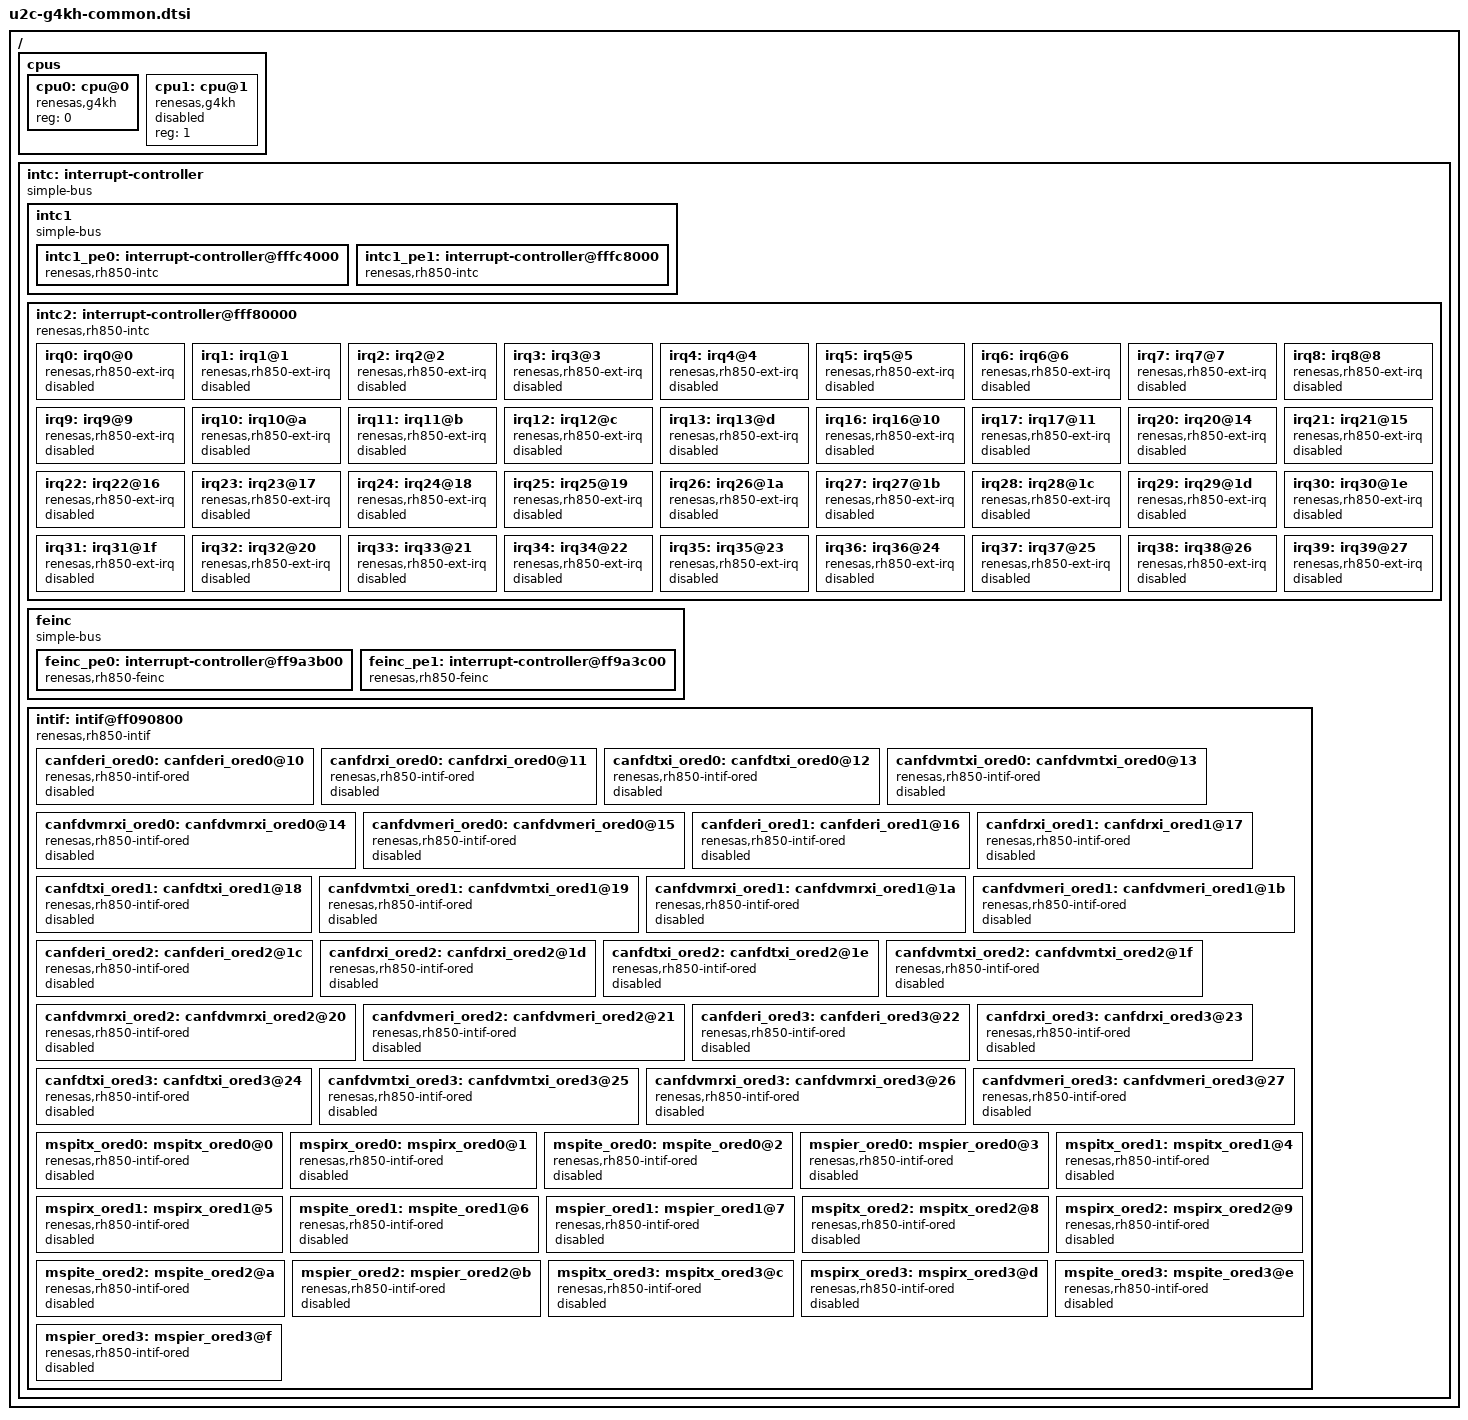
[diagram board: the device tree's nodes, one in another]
/*
 * Copyright (c) 2026 Renesas Electronics Corporation
 *
 * SPDX-License-Identifier: Apache-2.0
 */

#include <mem.h>
#include <freq.h>

/ {
	#address-cells = <1>;
	#size-cells = <1>;

	cpus {
		#address-cells = <1>;
		#size-cells = <0>;

		cpu0: cpu@0 {
			device_type = "cpu";
			compatible = "renesas,g4kh";
			reg = <0>;
			status = "okay";
		};

		cpu1: cpu@1 {
			device_type = "cpu";
			compatible = "renesas,g4kh";
			reg = <1>;
			status = "disabled";
		};
	};

	intc: interrupt-controller {
		#address-cells = <1>;
		#size-cells = <1>;
		compatible = "simple-bus";
		ranges;

		intc1: intc1 {
			#address-cells = <1>;
			#size-cells = <1>;
			compatible = "simple-bus";
			ranges;

			intc1_pe0: interrupt-controller@fffc4000 {
				#address-cells = <1>;
				#interrupt-cells = <2>;
				compatible = "renesas,rh850-intc";
				interrupt-controller;
				reg = <0xfffc4000 0x40>,
				      <0xfffc4100 0x80>;
				reg-names = "EIC", "EIBD";
				num-lines = <32>;
			};

			intc1_pe1: interrupt-controller@fffc8000 {
				#address-cells = <1>;
				#interrupt-cells = <2>;
				compatible = "renesas,rh850-intc";
				interrupt-controller;
				reg = <0xfffc8000 0x40>,
				      <0xfffc8100 0x80>;
				reg-names = "EIC", "EIBD";
				num-lines = <32>;
			};
		};

		intc2: interrupt-controller@fff80000 {
			#address-cells = <1>;
			#size-cells = <0>;
			#interrupt-cells = <2>;
			compatible = "renesas,rh850-intc";
			interrupt-controller;
			reg = <0xfff80000 0x4ac>,
			      <0xfff82000 0x958>;
			reg-names = "EIC", "EIBD";
			num-lines = <992>;

			irq0: irq0@0 {
				#address-cells = <1>;
				compatible = "renesas,rh850-ext-irq";
				reg = <0x00>;
				interrupt-controller;
				interrupts = <218 1>;
				#interrupt-cells = <2>;
				#irq-cells = <1>;
				status = "disabled";
			};

			irq1: irq1@1 {
				#address-cells = <1>;
				compatible = "renesas,rh850-ext-irq";
				reg = <0x01>;
				interrupt-controller;
				interrupts = <219 1>;
				#interrupt-cells = <2>;
				#irq-cells = <1>;
				status = "disabled";
			};

			irq2: irq2@2 {
				#address-cells = <1>;
				compatible = "renesas,rh850-ext-irq";
				reg = <0x02>;
				interrupt-controller;
				interrupts = <220 1>;
				#interrupt-cells = <2>;
				#irq-cells = <1>;
				status = "disabled";
			};

			irq3: irq3@3 {
				#address-cells = <1>;
				compatible = "renesas,rh850-ext-irq";
				reg = <0x03>;
				interrupt-controller;
				interrupts = <221 1>;
				#interrupt-cells = <2>;
				#irq-cells = <1>;
				status = "disabled";
			};

			irq4: irq4@4 {
				#address-cells = <1>;
				compatible = "renesas,rh850-ext-irq";
				reg = <0x04>;
				interrupt-controller;
				interrupts = <222 1>;
				#interrupt-cells = <2>;
				#irq-cells = <1>;
				status = "disabled";
			};

			irq5: irq5@5 {
				#address-cells = <1>;
				compatible = "renesas,rh850-ext-irq";
				reg = <0x05>;
				interrupt-controller;
				interrupts = <223 1>;
				#interrupt-cells = <2>;
				#irq-cells = <1>;
				status = "disabled";
			};

			irq6: irq6@6 {
				#address-cells = <1>;
				compatible = "renesas,rh850-ext-irq";
				reg = <0x06>;
				interrupt-controller;
				interrupts = <584 1>;
				#interrupt-cells = <2>;
				#irq-cells = <1>;
				status = "disabled";
			};

			irq7: irq7@7 {
				#address-cells = <1>;
				compatible = "renesas,rh850-ext-irq";
				reg = <0x07>;
				interrupt-controller;
				interrupts = <585 1>;
				#interrupt-cells = <2>;
				#irq-cells = <1>;
				status = "disabled";
			};

			irq8: irq8@8 {
				#address-cells = <1>;
				compatible = "renesas,rh850-ext-irq";
				reg = <0x08>;
				interrupt-controller;
				interrupts = <586 1>;
				#interrupt-cells = <2>;
				#irq-cells = <1>;
				status = "disabled";
			};

			irq9: irq9@9 {
				#address-cells = <1>;
				compatible = "renesas,rh850-ext-irq";
				reg = <0x09>;
				interrupt-controller;
				interrupts = <587 1>;
				#interrupt-cells = <2>;
				#irq-cells = <1>;
				status = "disabled";
			};

			irq10: irq10@a {
				#address-cells = <1>;
				compatible = "renesas,rh850-ext-irq";
				reg = <0x0a>;
				interrupt-controller;
				interrupts = <588 1>;
				#interrupt-cells = <2>;
				#irq-cells = <1>;
				status = "disabled";
			};

			irq11: irq11@b {
				#address-cells = <1>;
				compatible = "renesas,rh850-ext-irq";
				reg = <0x0b>;
				interrupt-controller;
				interrupts = <589 1>;
				#interrupt-cells = <2>;
				#irq-cells = <1>;
				status = "disabled";
			};

			irq12: irq12@c {
				#address-cells = <1>;
				compatible = "renesas,rh850-ext-irq";
				reg = <0x0c>;
				interrupt-controller;
				interrupts = <590 1>;
				#interrupt-cells = <2>;
				#irq-cells = <1>;
				status = "disabled";
			};

			irq13: irq13@d {
				#address-cells = <1>;
				compatible = "renesas,rh850-ext-irq";
				reg = <0x0d>;
				interrupt-controller;
				interrupts = <591 1>;
				#interrupt-cells = <2>;
				#irq-cells = <1>;
				status = "disabled";
			};

			irq16: irq16@10 {
				#address-cells = <1>;
				compatible = "renesas,rh850-ext-irq";
				reg = <0x10>;
				interrupt-controller;
				interrupts = <224 1>;
				#interrupt-cells = <2>;
				#irq-cells = <1>;
				status = "disabled";
			};

			irq17: irq17@11 {
				#address-cells = <1>;
				compatible = "renesas,rh850-ext-irq";
				reg = <0x11>;
				interrupt-controller;
				interrupts = <410 1>;
				#interrupt-cells = <2>;
				#irq-cells = <1>;
				status = "disabled";
			};

			irq20: irq20@14 {
				#address-cells = <1>;
				compatible = "renesas,rh850-ext-irq";
				reg = <0x14>;
				interrupt-controller;
				interrupts = <225 1>;
				#interrupt-cells = <2>;
				#irq-cells = <1>;
				status = "disabled";
			};

			irq21: irq21@15 {
				#address-cells = <1>;
				compatible = "renesas,rh850-ext-irq";
				reg = <0x15>;
				interrupt-controller;
				interrupts = <226 1>;
				#interrupt-cells = <2>;
				#irq-cells = <1>;
				status = "disabled";
			};

			irq22: irq22@16 {
				#address-cells = <1>;
				compatible = "renesas,rh850-ext-irq";
				reg = <0x16>;
				interrupt-controller;
				interrupts = <227 1>;
				#interrupt-cells = <2>;
				#irq-cells = <1>;
				status = "disabled";
			};

			irq23: irq23@17 {
				#address-cells = <1>;
				compatible = "renesas,rh850-ext-irq";
				reg = <0x17>;
				interrupt-controller;
				interrupts = <228 1>;
				#interrupt-cells = <2>;
				#irq-cells = <1>;
				status = "disabled";
			};

			irq24: irq24@18 {
				#address-cells = <1>;
				compatible = "renesas,rh850-ext-irq";
				reg = <0x18>;
				interrupt-controller;
				interrupts = <229 1>;
				#interrupt-cells = <2>;
				#irq-cells = <1>;
				status = "disabled";
			};

			irq25: irq25@19 {
				#address-cells = <1>;
				compatible = "renesas,rh850-ext-irq";
				reg = <0x19>;
				interrupt-controller;
				interrupts = <230 1>;
				#interrupt-cells = <2>;
				#irq-cells = <1>;
				status = "disabled";
			};

			irq26: irq26@1a {
				#address-cells = <1>;
				compatible = "renesas,rh850-ext-irq";
				reg = <0x1a>;
				interrupt-controller;
				interrupts = <231 1>;
				#interrupt-cells = <2>;
				#irq-cells = <1>;
				status = "disabled";
			};

			irq27: irq27@1b {
				#address-cells = <1>;
				compatible = "renesas,rh850-ext-irq";
				reg = <0x1b>;
				interrupt-controller;
				interrupts = <232 1>;
				#interrupt-cells = <2>;
				#irq-cells = <1>;
				status = "disabled";
			};

			irq28: irq28@1c {
				#address-cells = <1>;
				compatible = "renesas,rh850-ext-irq";
				reg = <0x1c>;
				interrupt-controller;
				interrupts = <411 1>;
				#interrupt-cells = <2>;
				#irq-cells = <1>;
				status = "disabled";
			};

			irq29: irq29@1d {
				#address-cells = <1>;
				compatible = "renesas,rh850-ext-irq";
				reg = <0x1d>;
				interrupt-controller;
				interrupts = <412 1>;
				#interrupt-cells = <2>;
				#irq-cells = <1>;
				status = "disabled";
			};

			irq30: irq30@1e {
				#address-cells = <1>;
				compatible = "renesas,rh850-ext-irq";
				reg = <0x1e>;
				interrupt-controller;
				interrupts = <413 1>;
				#interrupt-cells = <2>;
				#irq-cells = <1>;
				status = "disabled";
			};

			irq31: irq31@1f {
				#address-cells = <1>;
				compatible = "renesas,rh850-ext-irq";
				reg = <0x1f>;
				interrupt-controller;
				interrupts = <414 1>;
				#interrupt-cells = <2>;
				#irq-cells = <1>;
				status = "disabled";
			};

			irq32: irq32@20 {
				#address-cells = <1>;
				compatible = "renesas,rh850-ext-irq";
				reg = <0x20>;
				interrupt-controller;
				interrupts = <415 1>;
				#interrupt-cells = <2>;
				#irq-cells = <1>;
				status = "disabled";
			};

			irq33: irq33@21 {
				#address-cells = <1>;
				compatible = "renesas,rh850-ext-irq";
				reg = <0x21>;
				interrupt-controller;
				interrupts = <416 1>;
				#interrupt-cells = <2>;
				#irq-cells = <1>;
				status = "disabled";
			};

			irq34: irq34@22 {
				#address-cells = <1>;
				compatible = "renesas,rh850-ext-irq";
				reg = <0x22>;
				interrupt-controller;
				interrupts = <417 1>;
				#interrupt-cells = <2>;
				#irq-cells = <1>;
				status = "disabled";
			};

			irq35: irq35@23 {
				#address-cells = <1>;
				compatible = "renesas,rh850-ext-irq";
				reg = <0x23>;
				interrupt-controller;
				interrupts = <418 1>;
				#interrupt-cells = <2>;
				#irq-cells = <1>;
				status = "disabled";
			};

			irq36: irq36@24 {
				#address-cells = <1>;
				compatible = "renesas,rh850-ext-irq";
				reg = <0x24>;
				interrupt-controller;
				interrupts = <592 1>;
				#interrupt-cells = <2>;
				#irq-cells = <1>;
				status = "disabled";
			};

			irq37: irq37@25 {
				#address-cells = <1>;
				compatible = "renesas,rh850-ext-irq";
				reg = <0x25>;
				interrupt-controller;
				interrupts = <593 1>;
				#interrupt-cells = <2>;
				#irq-cells = <1>;
				status = "disabled";
			};

			irq38: irq38@26 {
				#address-cells = <1>;
				compatible = "renesas,rh850-ext-irq";
				reg = <0x26>;
				interrupt-controller;
				interrupts = <594 1>;
				#interrupt-cells = <2>;
				#irq-cells = <1>;
				status = "disabled";
			};

			irq39: irq39@27 {
				#address-cells = <1>;
				compatible = "renesas,rh850-ext-irq";
				reg = <0x27>;
				interrupt-controller;
				interrupts = <595 1>;
				#interrupt-cells = <2>;
				#irq-cells = <1>;
				status = "disabled";
			};
		};

		feinc: feinc {
			#address-cells = <1>;
			#size-cells = <1>;
			compatible = "simple-bus";
			ranges;

			feinc_pe0: interrupt-controller@ff9a3b00 {
				#address-cells = <1>;
				#interrupt-cells = <1>;
				compatible = "renesas,rh850-feinc";
				interrupt-controller;
				reg = <0xff9a3b00 0x4>,
				      <0xff9a3b04 0x4>,
				      <0xff9a3b08 0x4>;
				reg-names = "FEINTF", "FEINTMSK", "FEINTC";
				num-lines = <3>;
			};

			feinc_pe1: interrupt-controller@ff9a3c00 {
				#address-cells = <1>;
				#interrupt-cells = <1>;
				compatible = "renesas,rh850-feinc";
				interrupt-controller;
				reg = <0xff9a3c00 0x4>,
				      <0xff9a3c04 0x4>,
				      <0xff9a3c08 0x4>;
				reg-names = "FEINTF", "FEINTMSK", "FEINTC";
				num-lines = <3>;
			};
		};

		intif: intif@ff090800 {
			#address-cells = <1>;
			#size-cells = <0>;
			interrupt-parent = <&intc2>;
			compatible = "renesas,rh850-intif";
			reg = <0xff090800 0x13c>;

			canfderi_ored0: canfderi_ored0@10 {
				compatible = "renesas,rh850-intif-ored";
				#address-cells = <0>;
				reg = <0x10>;
				channel = <0>;
				interrupt-controller;
				interrupts = <106 1>;
				#interrupt-cells = <0>;
				status = "disabled";
			};

			canfdrxi_ored0: canfdrxi_ored0@11 {
				compatible = "renesas,rh850-intif-ored";
				#address-cells = <0>;
				reg = <0x11>;
				channel = <0>;
				interrupt-controller;
				interrupts = <107 1>;
				#interrupt-cells = <0>;
				status = "disabled";
			};

			canfdtxi_ored0: canfdtxi_ored0@12 {
				compatible = "renesas,rh850-intif-ored";
				#address-cells = <0>;
				reg = <0x12>;
				channel = <0>;
				interrupt-controller;
				interrupts = <108 1>;
				#interrupt-cells = <0>;
				status = "disabled";
			};

			canfdvmtxi_ored0: canfdvmtxi_ored0@13 {
				compatible = "renesas,rh850-intif-ored";
				#address-cells = <0>;
				reg = <0x13>;
				channel = <0>;
				interrupt-controller;
				interrupts = <109 1>;
				#interrupt-cells = <0>;
				status = "disabled";
			};

			canfdvmrxi_ored0: canfdvmrxi_ored0@14 {
				compatible = "renesas,rh850-intif-ored";
				#address-cells = <0>;
				reg = <0x14>;
				channel = <0>;
				interrupt-controller;
				interrupts = <110 1>;
				#interrupt-cells = <0>;
				status = "disabled";
			};

			canfdvmeri_ored0: canfdvmeri_ored0@15 {
				compatible = "renesas,rh850-intif-ored";
				#address-cells = <0>;
				reg = <0x15>;
				channel = <0>;
				interrupt-controller;
				interrupts = <111 1>;
				#interrupt-cells = <0>;
				status = "disabled";
			};

			canfderi_ored1: canfderi_ored1@16 {
				compatible = "renesas,rh850-intif-ored";
				#address-cells = <0>;
				reg = <0x16>;
				channel = <1>;
				interrupt-controller;
				interrupts = <112 1>;
				#interrupt-cells = <0>;
				status = "disabled";
			};

			canfdrxi_ored1: canfdrxi_ored1@17 {
				compatible = "renesas,rh850-intif-ored";
				#address-cells = <0>;
				reg = <0x17>;
				channel = <1>;
				interrupt-controller;
				interrupts = <113 1>;
				#interrupt-cells = <0>;
				status = "disabled";
			};

			canfdtxi_ored1: canfdtxi_ored1@18 {
				compatible = "renesas,rh850-intif-ored";
				#address-cells = <0>;
				reg = <0x18>;
				channel = <1>;
				interrupt-controller;
				interrupts = <114 1>;
				#interrupt-cells = <0>;
				status = "disabled";
			};

			canfdvmtxi_ored1: canfdvmtxi_ored1@19 {
				compatible = "renesas,rh850-intif-ored";
				#address-cells = <0>;
				reg = <0x19>;
				channel = <1>;
				interrupt-controller;
				interrupts = <115 1>;
				#interrupt-cells = <0>;
				status = "disabled";
			};

			canfdvmrxi_ored1: canfdvmrxi_ored1@1a {
				compatible = "renesas,rh850-intif-ored";
				#address-cells = <0>;
				reg = <0x1a>;
				channel = <1>;
				interrupt-controller;
				interrupts = <116 1>;
				#interrupt-cells = <0>;
				status = "disabled";
			};

			canfdvmeri_ored1: canfdvmeri_ored1@1b {
				compatible = "renesas,rh850-intif-ored";
				#address-cells = <0>;
				reg = <0x1b>;
				channel = <1>;
				interrupt-controller;
				interrupts = <117 1>;
				#interrupt-cells = <0>;
				status = "disabled";
			};

			canfderi_ored2: canfderi_ored2@1c {
				compatible = "renesas,rh850-intif-ored";
				#address-cells = <0>;
				reg = <0x1c>;
				channel = <2>;
				interrupt-controller;
				interrupts = <118 1>;
				#interrupt-cells = <0>;
				status = "disabled";
			};

			canfdrxi_ored2: canfdrxi_ored2@1d {
				compatible = "renesas,rh850-intif-ored";
				#address-cells = <0>;
				reg = <0x1d>;
				channel = <2>;
				interrupt-controller;
				interrupts = <119 1>;
				#interrupt-cells = <0>;
				status = "disabled";
			};

			canfdtxi_ored2: canfdtxi_ored2@1e {
				compatible = "renesas,rh850-intif-ored";
				#address-cells = <0>;
				reg = <0x1e>;
				channel = <2>;
				interrupt-controller;
				interrupts = <120 1>;
				#interrupt-cells = <0>;
				status = "disabled";
			};

			canfdvmtxi_ored2: canfdvmtxi_ored2@1f {
				compatible = "renesas,rh850-intif-ored";
				#address-cells = <0>;
				reg = <0x1f>;
				channel = <2>;
				interrupt-controller;
				interrupts = <121 1>;
				#interrupt-cells = <0>;
				status = "disabled";
			};

			canfdvmrxi_ored2: canfdvmrxi_ored2@20 {
				compatible = "renesas,rh850-intif-ored";
				#address-cells = <0>;
				reg = <0x20>;
				channel = <2>;
				interrupt-controller;
				interrupts = <122 1>;
				#interrupt-cells = <0>;
				status = "disabled";
			};

			canfdvmeri_ored2: canfdvmeri_ored2@21 {
				compatible = "renesas,rh850-intif-ored";
				#address-cells = <0>;
				reg = <0x21>;
				channel = <2>;
				interrupt-controller;
				interrupts = <123 1>;
				#interrupt-cells = <0>;
				status = "disabled";
			};

			canfderi_ored3: canfderi_ored3@22 {
				compatible = "renesas,rh850-intif-ored";
				#address-cells = <0>;
				reg = <0x22>;
				channel = <3>;
				interrupt-controller;
				interrupts = <124 1>;
				#interrupt-cells = <0>;
				status = "disabled";
			};

			canfdrxi_ored3: canfdrxi_ored3@23 {
				compatible = "renesas,rh850-intif-ored";
				#address-cells = <0>;
				reg = <0x23>;
				channel = <3>;
				interrupt-controller;
				interrupts = <125 1>;
				#interrupt-cells = <0>;
				status = "disabled";
			};

			canfdtxi_ored3: canfdtxi_ored3@24 {
				compatible = "renesas,rh850-intif-ored";
				#address-cells = <0>;
				reg = <0x24>;
				channel = <3>;
				interrupt-controller;
				interrupts = <126 1>;
				#interrupt-cells = <0>;
				status = "disabled";
			};

			canfdvmtxi_ored3: canfdvmtxi_ored3@25 {
				compatible = "renesas,rh850-intif-ored";
				#address-cells = <0>;
				reg = <0x25>;
				channel = <3>;
				interrupt-controller;
				interrupts = <127 1>;
				#interrupt-cells = <0>;
				status = "disabled";
			};

			canfdvmrxi_ored3: canfdvmrxi_ored3@26 {
				compatible = "renesas,rh850-intif-ored";
				#address-cells = <0>;
				reg = <0x26>;
				channel = <3>;
				interrupt-controller;
				interrupts = <128 1>;
				#interrupt-cells = <0>;
				status = "disabled";
			};

			canfdvmeri_ored3: canfdvmeri_ored3@27 {
				compatible = "renesas,rh850-intif-ored";
				#address-cells = <0>;
				reg = <0x27>;
				channel = <3>;
				interrupt-controller;
				interrupts = <129 1>;
				#interrupt-cells = <0>;
				status = "disabled";
			};

			mspitx_ored0: mspitx_ored0@0 {
				compatible = "renesas,rh850-intif-ored";
				#address-cells = <0>;
				reg = <0x0>;
				channel = <0>;
				interrupt-controller;
				interrupts = <88 1>;
				#interrupt-cells = <0>;
				status = "disabled";
			};

			mspirx_ored0: mspirx_ored0@1 {
				compatible = "renesas,rh850-intif-ored";
				#address-cells = <0>;
				reg = <0x1>;
				channel = <0>;
				interrupt-controller;
				interrupts = <89 1>;
				#interrupt-cells = <0>;
				status = "disabled";
			};

			mspite_ored0: mspite_ored0@2 {
				compatible = "renesas,rh850-intif-ored";
				#address-cells = <0>;
				reg = <0x2>;
				channel = <0>;
				interrupt-controller;
				interrupts = <90 1>;
				#interrupt-cells = <0>;
				status = "disabled";
			};

			mspier_ored0: mspier_ored0@3 {
				compatible = "renesas,rh850-intif-ored";
				#address-cells = <0>;
				reg = <0x3>;
				channel = <0>;
				interrupt-controller;
				interrupts = <91 1>;
				#interrupt-cells = <0>;
				status = "disabled";
			};

			mspitx_ored1: mspitx_ored1@4 {
				compatible = "renesas,rh850-intif-ored";
				#address-cells = <0>;
				reg = <0x4>;
				channel = <1>;
				interrupt-controller;
				interrupts = <92 1>;
				#interrupt-cells = <0>;
				status = "disabled";
			};

			mspirx_ored1: mspirx_ored1@5 {
				compatible = "renesas,rh850-intif-ored";
				#address-cells = <0>;
				reg = <0x5>;
				channel = <1>;
				interrupt-controller;
				interrupts = <93 1>;
				#interrupt-cells = <0>;
				status = "disabled";
			};

			mspite_ored1: mspite_ored1@6 {
				compatible = "renesas,rh850-intif-ored";
				#address-cells = <0>;
				reg = <0x6>;
				channel = <1>;
				interrupt-controller;
				interrupts = <94 1>;
				#interrupt-cells = <0>;
				status = "disabled";
			};

			mspier_ored1: mspier_ored1@7 {
				compatible = "renesas,rh850-intif-ored";
				#address-cells = <0>;
				reg = <0x7>;
				channel = <1>;
				interrupt-controller;
				interrupts = <95 1>;
				#interrupt-cells = <0>;
				status = "disabled";
			};

			mspitx_ored2: mspitx_ored2@8 {
				compatible = "renesas,rh850-intif-ored";
				#address-cells = <0>;
				reg = <0x8>;
				channel = <2>;
				interrupt-controller;
				interrupts = <96 1>;
				#interrupt-cells = <0>;
				status = "disabled";
			};

			mspirx_ored2: mspirx_ored2@9 {
				compatible = "renesas,rh850-intif-ored";
				#address-cells = <0>;
				reg = <0x9>;
				channel = <2>;
				interrupt-controller;
				interrupts = <97 1>;
				#interrupt-cells = <0>;
				status = "disabled";
			};

			mspite_ored2: mspite_ored2@a {
				compatible = "renesas,rh850-intif-ored";
				#address-cells = <0>;
				reg = <0xa>;
				channel = <2>;
				interrupt-controller;
				interrupts = <98 1>;
				#interrupt-cells = <0>;
				status = "disabled";
			};

			mspier_ored2: mspier_ored2@b {
				compatible = "renesas,rh850-intif-ored";
				#address-cells = <0>;
				reg = <0xb>;
				channel = <2>;
				interrupt-controller;
				interrupts = <99 1>;
				#interrupt-cells = <0>;
				status = "disabled";
			};

			mspitx_ored3: mspitx_ored3@c {
				compatible = "renesas,rh850-intif-ored";
				#address-cells = <0>;
				reg = <0xc>;
				channel = <3>;
				interrupt-controller;
				interrupts = <100 1>;
				#interrupt-cells = <0>;
				status = "disabled";
			};

			mspirx_ored3: mspirx_ored3@d {
				compatible = "renesas,rh850-intif-ored";
				#address-cells = <0>;
				reg = <0xd>;
				channel = <3>;
				interrupt-controller;
				interrupts = <101 1>;
				#interrupt-cells = <0>;
				status = "disabled";
			};

			mspite_ored3: mspite_ored3@e {
				compatible = "renesas,rh850-intif-ored";
				#address-cells = <0>;
				reg = <0xe>;
				channel = <3>;
				interrupt-controller;
				interrupts = <102 1>;
				#interrupt-cells = <0>;
				status = "disabled";
			};

			mspier_ored3: mspier_ored3@f {
				compatible = "renesas,rh850-intif-ored";
				#address-cells = <0>;
				reg = <0xf>;
				channel = <3>;
				interrupt-controller;
				interrupts = <103 1>;
				#interrupt-cells = <0>;
				status = "disabled";
			};
		};
	};
};
